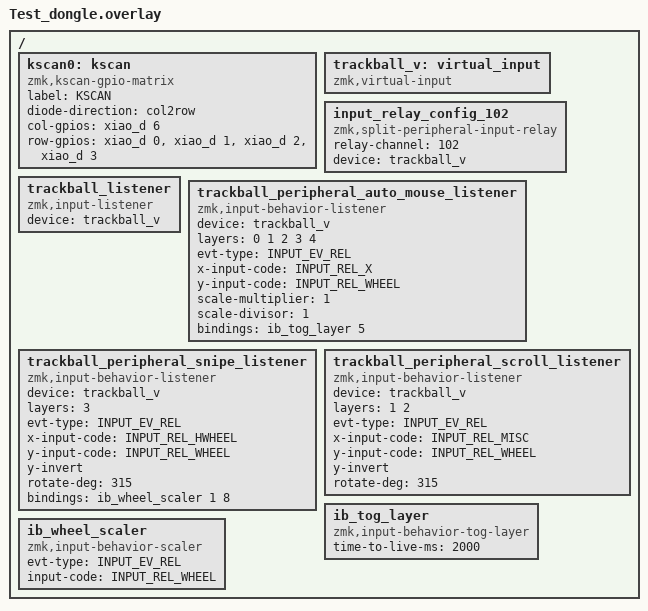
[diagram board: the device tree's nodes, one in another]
#include "Test.dtsi"
#include "Test_trackball.dtsi"

/ {
    kscan0: kscan {
        compatible = "zmk,kscan-gpio-matrix";
        label = "KSCAN";
        diode-direction = "col2row";
    col-gpios
        = <&xiao_d 6 GPIO_ACTIVE_HIGH>
        ;
    row-gpios
    = <&xiao_d 0 (GPIO_ACTIVE_HIGH | GPIO_PULL_DOWN)>
    , <&xiao_d 1 (GPIO_ACTIVE_HIGH | GPIO_PULL_DOWN)>
    , <&xiao_d 2 (GPIO_ACTIVE_HIGH | GPIO_PULL_DOWN)>
    , <&xiao_d 3 (GPIO_ACTIVE_HIGH | GPIO_PULL_DOWN)>
    ;
    };
};

/ {
	/* define virtual input, will be resurrected for emitting input event */
	/* NOTE: set `device = <&pd1>` in `zmk,input-listener` */
	trackball_v: virtual_input {
		compatible = "zmk,virtual-input";
	};
};

/ {
	/* for central side, define (relay-channel)-to-(virtual-input) mapping */
	input_relay_config_102 {
		compatible = "zmk,split-peripheral-input-relay";
		
		/* channel id, used to filter incoming annotated input event from split peripheral */
		/* NOTE: should matching relay-channel on peripheral overlay */
		relay-channel = <102>;

		/* virtual input device on central, which used to emit input event as an agent device */
		device = <&trackball_v>;
	};
};

/{
  trackball_listener { 
    compatible = "zmk,input-listener";
    device = <&trackball_v>;
  };
};

/{
  /* auto toggle mouse key layer */
  trackball_peripheral_auto_mouse_listener {
        compatible = "zmk,input-behavior-listener";
        device = <&trackball_v>;
        layers = <0 1 2 3 4>;
		evt-type = <INPUT_EV_REL>;
		x-input-code = <INPUT_REL_X>;
		y-input-code = <INPUT_REL_WHEEL>;
		scale-multiplier = <1>;
		scale-divisor = <1>;
        bindings = <&ib_tog_layer 5>;
   };

      /* input config for mouse scroll mode on momentary mouse scoll layer */
   trackball_peripheral_snipe_listener {
           compatible = "zmk,input-behavior-listener";
           device = <&trackball_v>;
           layers = <3>;
           evt-type = <INPUT_EV_REL>;
           
           /* slienting x-axis with alt event code */
           x-input-code = <INPUT_REL_HWHEEL>;
           y-input-code = <INPUT_REL_WHEEL>;   
           /* invent scrolling direction */
           y-invert;
           /* align to CCW 45 degree */
           rotate-deg = <315>;
           /* NOTE 1: This settings do not compitable with y-invert and x-invert */
           /* NOTE 2: Floating point computation requires alot of ram. */
           /*         This feature will cuase stackove flow with CONFIG_ZMK_USB_LOGGING=y *   
           /* bind a behavior to down scaling input value to (1/8) */
           /* NOTE: This behavior is different to scale-divisor. */
           /*       The delta value is accumlated until result >= 1 after cast. */
           /*       The scrolling is preented in hi-res and allow precise scrolling */
           bindings = <&ib_wheel_scaler 1 8>;
   };

   /* the binding input behavior is a scrolling layer */
   trackball_peripheral_scroll_listener {
           compatible = "zmk,input-behavior-listener";
           device = <&trackball_v>;
           layers = <1 2>;
           evt-type = <INPUT_EV_REL>;
           
           /* slienting x-axis with alt event code */
           x-input-code = <INPUT_REL_MISC>;
           y-input-code = <INPUT_REL_WHEEL>;
           /* invent scrolling direction */
           y-invert;
           /* align to CCW 45 degree */
           rotate-deg = <315>;
   };

   /* adjust cooldown waiting period for mouse key layer (MSK) after activated */
   ib_tog_layer: ib_tog_layer {
        compatible = "zmk,input-behavior-tog-layer";
        #binding-cells = <1>;
        time-to-live-ms = <2000>;
    };

    /* define a resolution down scaler only for INPUT_REL_WHEEL */
    ib_wheel_scaler: ib_wheel_scaler {
            compatible = "zmk,input-behavior-scaler";
            #binding-cells = <2>;
            evt-type = <INPUT_EV_REL>;
            input-code = <INPUT_REL_WHEEL>;
    };
};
